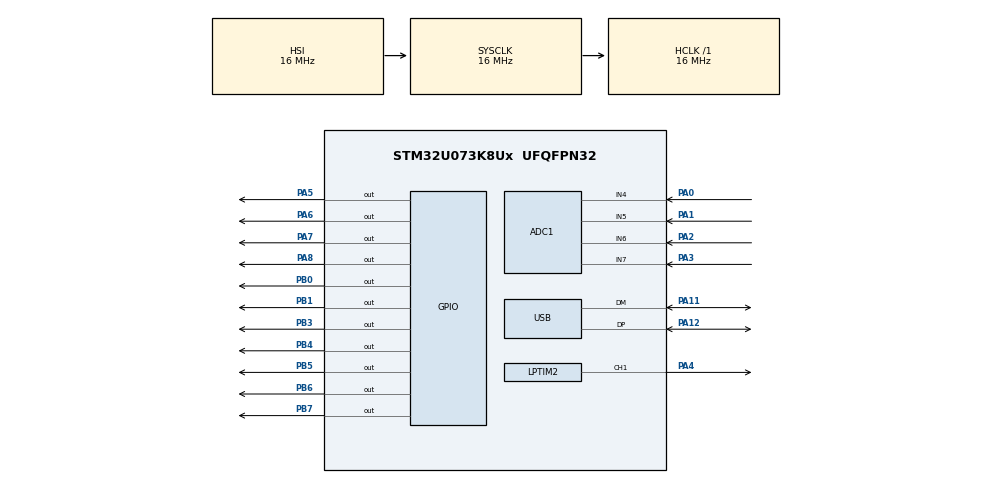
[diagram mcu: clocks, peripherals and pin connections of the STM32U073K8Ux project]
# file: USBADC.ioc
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ADC1.Channel-0\#ChannelRegularConversion=ADC_CHANNEL_4
ADC1.NbrOfConversionFlag=1
ADC1.Rank-0\#ChannelRegularConversion=1
ADC1.RankArg-0\#ChannelRegularConversion=ADC_REGULAR_RANK_1
ADC1.SamplingTime-0\#ChannelRegularConversion=ADC_SAMPLINGTIME_COMMON_1
ADC1.SelectedChannel=ADC_CHANNEL_4|ADC_CHANNEL_5|ADC_CHANNEL_6|ADC_CHANNEL_7
ADC1.master=1
LPTIM2.Period=639
Mcu.Family=STM32U0
Mcu.Name=STM32U073K8Ux
Mcu.Package=UFQFPN32
NVIC.PriorityGroup=NVIC_PRIORITYGROUP_2
NVIC.TIM1_BRK_UP_TRG_COM_IRQn=true\:3\:0\:false\:false\:true\:false\:false\:true\:true
NVIC.TimeBase=TIM1_BRK_UP_TRG_COM_IRQn
NVIC.TimeBaseIP=TIM1
NVIC.USB_DRD_FS_IRQn=true\:0\:0\:false\:false\:true\:false\:true\:true\:true
PA0-CK_IN.Mode=IN4
PA0-CK_IN.Signal=ADC1_IN4
PA1.Mode=IN5
PA1.Signal=ADC1_IN5
PA11\ [PA9].Mode=Device
PA11\ [PA9].Signal=USB_DM
PA12\ [PA10].Mode=Device
PA12\ [PA10].Signal=USB_DP
PA2.Mode=IN6
PA2.Signal=ADC1_IN6
PA3.Mode=IN7
PA3.Signal=ADC1_IN7
PA4.Signal=S_LPTIM2_CH1
PA5.Signal=GPIO_Output
PA6.Signal=GPIO_Output
PA7.Signal=GPIO_Output
PA8.Signal=GPIO_Output
PB0.Signal=GPIO_Output
PB1.Signal=GPIO_Output
PB3.Signal=GPIO_Output
PB4.Signal=GPIO_Output
PB5.Signal=GPIO_Output
PB6.Signal=GPIO_Output
PB7.Signal=GPIO_Output
ProjectManager.HeapSize=0x200
ProjectManager.StackSize=0x400
ProjectManager.TargetToolchain=Makefile
RCC.AHBFreq_Value=16000000
RCC.CortexFreq_Value=16000000
RCC.HCLKFreq_Value=16000000
RCC.HSE_VALUE=4000000
RCC.HSI48_VALUE=48000000
RCC.HSI_VALUE=16000000
RCC.LSE_VALUE=32768
RCC.MSIClockRangeVal=RCC_MSIRANGE_11
RCC.MSI_VALUE=48000000
RCC.SYSCLKFreq_VALUE=16000000
RCC.USBFreq_Value=48000000
RCC.VCOOutputFreq_Value=64000000
SH.S_LPTIM2_CH1.0=LPTIM2_CH1,OutputIO_CH1
THREADX.TX_APP_MEM_POOL_SIZE=1024 * 3
USB.VirtualMode=Device_Only
USBX.BSP.number=1
USBX.Core_System=1
USBX.USBD_CDCACM_EPINCMD_ADDR=3
USBX.USBD_CDCACM_EPIN_ADDR=2
USBX.USBD_MANUFACTURER_STRING=BocquelLab
USBX.USBD_PID=0x0001
USBX.USBD_PRODUCT_STRING=USBADC
USBX.USBD_VID=0xFFFF
USBX.USBX_DEVICE_SYS_SIZE=10 * 1024
USBX.UX_DEVICE_APP_MEM_POOL_SIZE=1024 * 20
USBX.UX_DEVICE_CDC_ACM=1
USBX.UX_Device_Controller=1
USBX.UX_Device_CoreStack=1
USBX0.BSP.STBoard=false
USBX0.BSP.api=Unknown
USBX0.BSP.instance=USB
USBX0.BSP.ip=USB
USBX0.BSP.mode=Device_Only
USBX0.BSP.name=USB_Device
USBX0.BSP.solution=USB
VP_LPTIM2_VS_CH1.Mode=Channel_1_Active
VP_LPTIM2_VS_LPTIM_counterModeInternalClock.Mode=Counts__internal_clock_event_00
VP_PWR_VS_SECSignals.Mode=Security/Privilege
VP_RCC_USB.Mode=CRS SYNC Source USB
VP_SYS_VS_tim1.Mode=TIM1
VP_THREADX_VS_RTOSJjThreadXJjCoreJjDefault.Mode=Core_Default
VP_USBX_Core_System.Mode=Core_System
VP_USBX_UX\ Device\ CDC\ ACM\ Class_FS.Mode=UX_Device_class_CDC_ACM_FS
VP_USBX_UX\ Device\ Controller_FS.Mode=UX_Device_Controller_FS
VP_USBX_UX\ Device\ CoreStack_FS.Mode=UX_Device_CoreStack_FS
board=custom

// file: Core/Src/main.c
/* USER CODE BEGIN Header */
/* USER CODE END Header */
#include "app_threadx.h"
#include "main.h"

ADC_HandleTypeDef hadc1;

LPTIM_HandleTypeDef hlptim2;

PCD_HandleTypeDef hpcd_USB_DRD_FS;

void SystemClock_Config(void);
static void MX_GPIO_Init(void);
static void MX_ADC1_Init(void);
static void MX_LPTIM2_Init(void);

int main(void)
{

  /* MCU Configuration--------------------------------------------------------*/

  /* Reset of all peripherals, Initializes the Flash interface and the Systick. */
  HAL_Init();

  /* Configure the system clock */
  SystemClock_Config();

  /* Initialize all configured peripherals */
  MX_GPIO_Init();
  MX_ADC1_Init();
  MX_LPTIM2_Init();

  MX_ThreadX_Init();

  /* We should never get here as control is now taken by the scheduler */

  /* Infinite loop */

}

void SystemClock_Config(void)
{
  RCC_OscInitTypeDef RCC_OscInitStruct = {0};
  RCC_ClkInitTypeDef RCC_ClkInitStruct = {0};
  RCC_CRSInitTypeDef RCC_CRSInitStruct = {0};

  /** Configure the main internal regulator output voltage
  */
  HAL_PWREx_ControlVoltageScaling(PWR_REGULATOR_VOLTAGE_SCALE2);

  /** Initializes the RCC Oscillators according to the specified parameters
  * in the RCC_OscInitTypeDef structure.
  */
  RCC_OscInitStruct.OscillatorType = RCC_OSCILLATORTYPE_HSI|RCC_OSCILLATORTYPE_MSI;
  RCC_OscInitStruct.HSIState = RCC_HSI_ON;
  RCC_OscInitStruct.HSICalibrationValue = RCC_HSICALIBRATION_DEFAULT;
  RCC_OscInitStruct.MSIState = RCC_MSI_ON;
  RCC_OscInitStruct.MSICalibrationValue = RCC_MSICALIBRATION_DEFAULT;
  RCC_OscInitStruct.MSIClockRange = RCC_MSIRANGE_11;
  RCC_OscInitStruct.PLL.PLLState = RCC_PLL_NONE;
  if (HAL_RCC_OscConfig(&RCC_OscInitStruct) != HAL_OK)
  {
    Error_Handler();
  }

  /** Initializes the CPU, AHB and APB buses clocks
  */
  RCC_ClkInitStruct.ClockType = RCC_CLOCKTYPE_HCLK|RCC_CLOCKTYPE_SYSCLK
                              |RCC_CLOCKTYPE_PCLK1;
  RCC_ClkInitStruct.SYSCLKSource = RCC_SYSCLKSOURCE_HSI;
  RCC_ClkInitStruct.AHBCLKDivider = RCC_SYSCLK_DIV1;
  RCC_ClkInitStruct.APB1CLKDivider = RCC_HCLK_DIV1;

  if (HAL_RCC_ClockConfig(&RCC_ClkInitStruct, FLASH_LATENCY_1) != HAL_OK)
  {
    Error_Handler();
  }

  /** Enable the CRS clock
  */
  __HAL_RCC_CRS_CLK_ENABLE();

  /** Configures CRS
  */
  RCC_CRSInitStruct.Prescaler = RCC_CRS_SYNC_DIV1;
  RCC_CRSInitStruct.Source = RCC_CRS_SYNC_SOURCE_USB;
  RCC_CRSInitStruct.Polarity = RCC_CRS_SYNC_POLARITY_RISING;
  RCC_CRSInitStruct.ReloadValue = __HAL_RCC_CRS_RELOADVALUE_CALCULATE(48000000,1000);
  RCC_CRSInitStruct.ErrorLimitValue = 34;
  RCC_CRSInitStruct.HSI48CalibrationValue = 32;

  HAL_RCCEx_CRSConfig(&RCC_CRSInitStruct);
}

static void MX_ADC1_Init(void)
{

  ADC_ChannelConfTypeDef sConfig = {0};

  /** Configure the global features of the ADC (Clock, Resolution, Data Alignment and number of conversion)
  */
  hadc1.Instance = ADC1;
  hadc1.Init.ClockPrescaler = ADC_CLOCK_SYNC_PCLK_DIV1;
  hadc1.Init.Resolution = ADC_RESOLUTION_12B;
  hadc1.Init.DataAlign = ADC_DATAALIGN_RIGHT;
  hadc1.Init.ScanConvMode = ADC_SCAN_DISABLE;
  hadc1.Init.EOCSelection = ADC_EOC_SINGLE_CONV;
  hadc1.Init.LowPowerAutoWait = DISABLE;
  hadc1.Init.LowPowerAutoPowerOff = DISABLE;
  hadc1.Init.ContinuousConvMode = DISABLE;
  hadc1.Init.NbrOfConversion = 1;
  hadc1.Init.DiscontinuousConvMode = DISABLE;
  hadc1.Init.ExternalTrigConv = ADC_SOFTWARE_START;
  hadc1.Init.ExternalTrigConvEdge = ADC_EXTERNALTRIGCONVEDGE_NONE;
  hadc1.Init.DMAContinuousRequests = DISABLE;
  hadc1.Init.Overrun = ADC_OVR_DATA_PRESERVED;
  hadc1.Init.SamplingTimeCommon1 = ADC_SAMPLETIME_1CYCLE_5;
  hadc1.Init.SamplingTimeCommon2 = ADC_SAMPLETIME_1CYCLE_5;
  hadc1.Init.OversamplingMode = DISABLE;
  hadc1.Init.TriggerFrequencyMode = ADC_TRIGGER_FREQ_HIGH;
  if (HAL_ADC_Init(&hadc1) != HAL_OK)
  {
    Error_Handler();
  }

  /** Configure Regular Channel
  */
  sConfig.Channel = ADC_CHANNEL_4;
  sConfig.Rank = ADC_REGULAR_RANK_1;
  sConfig.SamplingTime = ADC_SAMPLINGTIME_COMMON_1;
  if (HAL_ADC_ConfigChannel(&hadc1, &sConfig) != HAL_OK)
  {
    Error_Handler();
  }

}

static void MX_LPTIM2_Init(void)
{

  LPTIM_OC_ConfigTypeDef sConfig1 = {0};

  hlptim2.Instance = LPTIM2;
  hlptim2.Init.Clock.Source = LPTIM_CLOCKSOURCE_APBCLOCK_LPOSC;
  hlptim2.Init.Clock.Prescaler = LPTIM_PRESCALER_DIV1;
  hlptim2.Init.Trigger.Source = LPTIM_TRIGSOURCE_SOFTWARE;
  hlptim2.Init.Period = 639;
  hlptim2.Init.UpdateMode = LPTIM_UPDATE_IMMEDIATE;
  hlptim2.Init.CounterSource = LPTIM_COUNTERSOURCE_INTERNAL;
  hlptim2.Init.Input1Source = LPTIM_INPUT1SOURCE_GPIO;
  hlptim2.Init.RepetitionCounter = 0;
  if (HAL_LPTIM_Init(&hlptim2) != HAL_OK)
  {
    Error_Handler();
  }
  sConfig1.Pulse = 0;
  sConfig1.OCPolarity = LPTIM_OCPOLARITY_HIGH;
  if (HAL_LPTIM_OC_ConfigChannel(&hlptim2, &sConfig1, LPTIM_CHANNEL_1) != HAL_OK)
  {
    Error_Handler();
  }
  /* USER CODE BEGIN LPTIM2_Init 2 */
  HAL_LPTIM_PWM_Start(&hlptim2, 1);
  /* USER CODE END LPTIM2_Init 2 */

}

void MX_USB_PCD_Init(void)
{

  hpcd_USB_DRD_FS.Instance = USB_DRD_FS;
  hpcd_USB_DRD_FS.Init.dev_endpoints = 8;
  hpcd_USB_DRD_FS.Init.speed = USBD_FS_SPEED;
  hpcd_USB_DRD_FS.Init.phy_itface = PCD_PHY_EMBEDDED;
  hpcd_USB_DRD_FS.Init.Sof_enable = DISABLE;
  hpcd_USB_DRD_FS.Init.low_power_enable = DISABLE;
  hpcd_USB_DRD_FS.Init.lpm_enable = DISABLE;
  hpcd_USB_DRD_FS.Init.battery_charging_enable = DISABLE;
  if (HAL_PCD_Init(&hpcd_USB_DRD_FS) != HAL_OK)
  {
    Error_Handler();
  }

}

static void MX_GPIO_Init(void)
{
  GPIO_InitTypeDef GPIO_InitStruct = {0};

  /* GPIO Ports Clock Enable */
  __HAL_RCC_GPIOA_CLK_ENABLE();
  __HAL_RCC_GPIOB_CLK_ENABLE();

  /*Configure GPIO pin Output Level */
  HAL_GPIO_WritePin(GPIOA, GPIO_PIN_5|GPIO_PIN_6|GPIO_PIN_7|GPIO_PIN_8, GPIO_PIN_RESET);

  /*Configure GPIO pin Output Level */
  HAL_GPIO_WritePin(GPIOB, GPIO_PIN_0|GPIO_PIN_1|GPIO_PIN_3|GPIO_PIN_4
                          |GPIO_PIN_5|GPIO_PIN_6|GPIO_PIN_7, GPIO_PIN_RESET);

  /*Configure GPIO pins : PA5 PA6 PA7 PA8 */
  GPIO_InitStruct.Pin = GPIO_PIN_5|GPIO_PIN_6|GPIO_PIN_7|GPIO_PIN_8;
  GPIO_InitStruct.Mode = GPIO_MODE_OUTPUT_PP;
  GPIO_InitStruct.Pull = GPIO_NOPULL;
  GPIO_InitStruct.Speed = GPIO_SPEED_FREQ_LOW;
  HAL_GPIO_Init(GPIOA, &GPIO_InitStruct);

  /*Configure GPIO pins : PB0 PB1 PB3 PB4
                           PB5 PB6 PB7 */
  GPIO_InitStruct.Pin = GPIO_PIN_0|GPIO_PIN_1|GPIO_PIN_3|GPIO_PIN_4
                          |GPIO_PIN_5|GPIO_PIN_6|GPIO_PIN_7;
  GPIO_InitStruct.Mode = GPIO_MODE_OUTPUT_PP;
  GPIO_InitStruct.Pull = GPIO_NOPULL;
  GPIO_InitStruct.Speed = GPIO_SPEED_FREQ_LOW;
  HAL_GPIO_Init(GPIOB, &GPIO_InitStruct);

}

void HAL_TIM_PeriodElapsedCallback(TIM_HandleTypeDef *htim)
{
  if (htim->Instance == TIM1)
  {
    HAL_IncTick();
  }
}

void Error_Handler(void)
{
  /* USER CODE BEGIN Error_Handler_Debug */
  // NVIC_SystemReset();
  /* USER CODE END Error_Handler_Debug */
}
